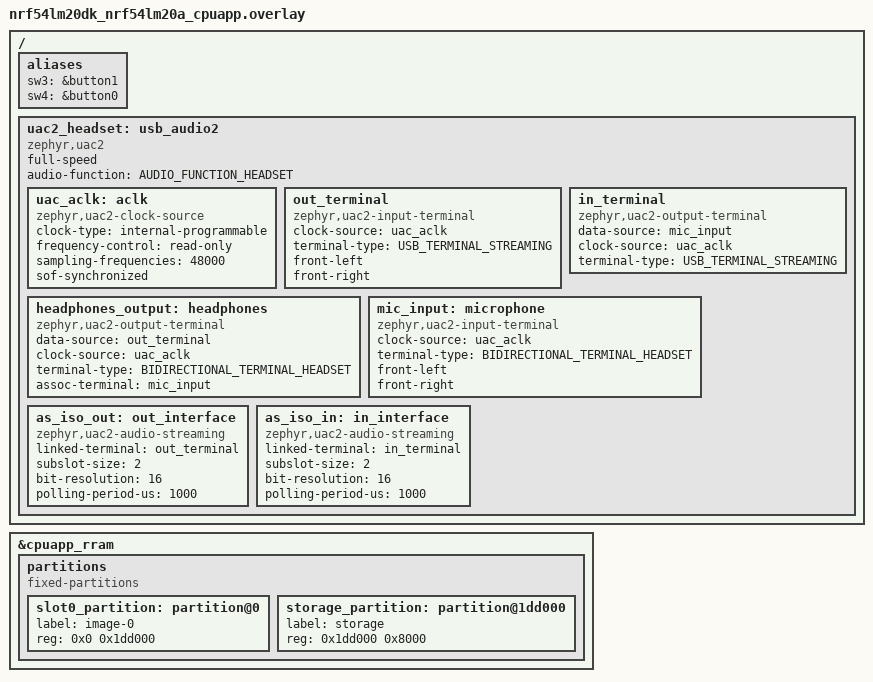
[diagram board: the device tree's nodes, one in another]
/*
 * Copyright (c) 2025 Nordic Semiconductor ASA
 *
 * SPDX-License-Identifier: LicenseRef-Nordic-5-Clause
 */

#include <dt-bindings/usb/audio.h>

/* nRF54LM20DK has 4 buttons (sw0-sw3), but the nRF7002EB2 shield deletes
 * button_3 / sw3 due to GPIO pin conflicts. Remap sw3 to button1 and sw4 to
 * button0 so all aliases resolve to UNIQUE GPIO pins (required to avoid
 * duplicate case values in main.c's button switch statement).
 * Only 3 physical buttons are functionally usable.
 */
/ {
	aliases {
		sw3 = &button1;
		sw4 = &button0;
	};
};

/* UAC2 (USB Audio Class 2.0) headset device — required by audio_usb.c
 * (DT_NODELABEL(uac2_headset)). The usbhs (DWC2) controller is forced to
 * Full-Speed (CONFIG_UDC_DRIVER_HIGH_SPEED_SUPPORT_ENABLED=n in the board conf)
 * because High-Speed enumeration broke the isochronous OUT audio stream on
 * macOS hosts. Full-Speed (1 ms / 192-byte packets) matches the audio FIFO
 * block sizing and is the validated-working mode.
 */
/ {
	uac2_headset: usb_audio2 {
		compatible = "zephyr,uac2";
		status = "okay";
		full-speed;
		audio-function = <AUDIO_FUNCTION_HEADSET>;

		uac_aclk: aclk {
			compatible = "zephyr,uac2-clock-source";
			clock-type = "internal-programmable";
			frequency-control = "read-only";
			sampling-frequencies = <48000>;
			sof-synchronized;
		};

		out_terminal: out_terminal {
			compatible = "zephyr,uac2-input-terminal";
			clock-source = <&uac_aclk>;
			terminal-type = <USB_TERMINAL_STREAMING>;
			front-left;
			front-right;
		};

		headphones_output: headphones {
			compatible = "zephyr,uac2-output-terminal";
			data-source = <&out_terminal>;
			clock-source = <&uac_aclk>;
			terminal-type = <BIDIRECTIONAL_TERMINAL_HEADSET>;
			assoc-terminal = <&mic_input>;
		};

		in_terminal: in_terminal {
			compatible = "zephyr,uac2-output-terminal";
			data-source = <&mic_input>;
			clock-source = <&uac_aclk>;
			terminal-type = <USB_TERMINAL_STREAMING>;
		};

		mic_input: microphone {
			compatible = "zephyr,uac2-input-terminal";
			clock-source = <&uac_aclk>;
			terminal-type = <BIDIRECTIONAL_TERMINAL_HEADSET>;
			front-left;
			front-right;
		};

		as_iso_out: out_interface {
			compatible = "zephyr,uac2-audio-streaming";
			linked-terminal = <&out_terminal>;
			subslot-size = <2>;
			bit-resolution = <16>;
			polling-period-us = <1000>;
		};

		as_iso_in: in_interface {
			compatible = "zephyr,uac2-audio-streaming";
			linked-terminal = <&in_terminal>;
			subslot-size = <2>;
			bit-resolution = <16>;
			polling-period-us = <1000>;
		};
	};
};

/* Single-image (no MCUboot) partition layout for nRF54LM20DK (nRF54LM20A RRAM).
 * nRF54LM20A has 2036 KB RRAM; last 96 KB reserved for FLPR → 1940 KB available.
 * slot0_partition : 0x000000 - 0x1dcfff  (1908 KB, app image)
 * storage_partition: 0x1dd000 - 0x1e4fff  (32 KB, NVS/settings)
 */
&cpuapp_rram {
	/delete-node/ partitions;

	partitions {
		compatible = "fixed-partitions";
		#address-cells = <1>;
		#size-cells = <1>;

		slot0_partition: partition@0 {
			label = "image-0";
			reg = <0x0 0x1dd000>;
		};

		storage_partition: partition@1dd000 {
			label = "storage";
			reg = <0x1dd000 0x8000>;
		};
	};
};
